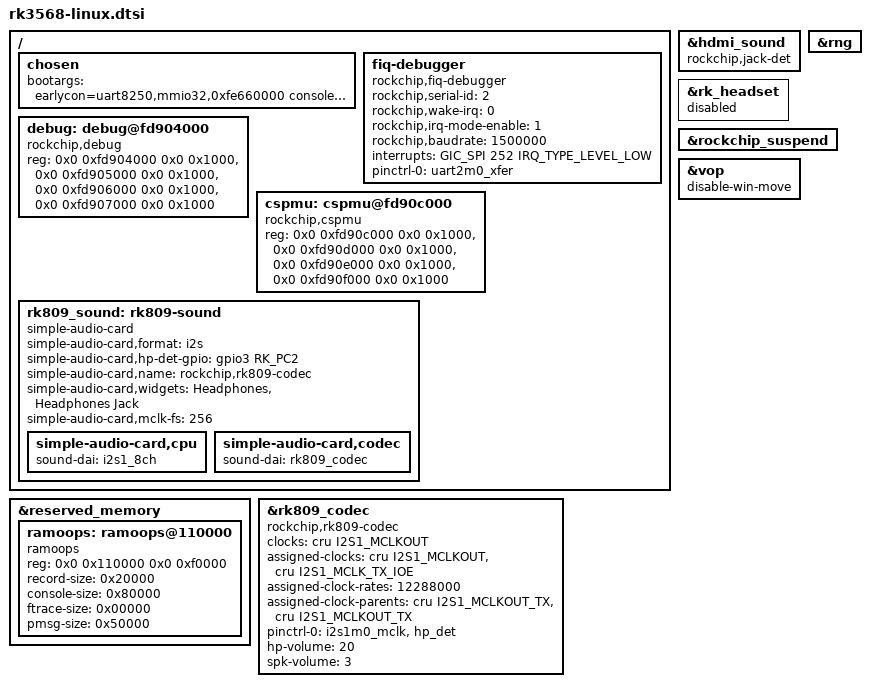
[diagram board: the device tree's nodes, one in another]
// SPDX-License-Identifier: (GPL-2.0+ OR MIT)
/*
 * Copyright (c) 2020 Rockchip Electronics Co., Ltd.
 *
 */

/ {
	chosen: chosen {
		bootargs = "earlycon=uart8250,mmio32,0xfe660000 console=ttyFIQ0 root=PARTLABEL=rootfs rootfstype=ext4 ro rootwait overlayroot=device:dev=PARTLABEL=userdata,fstype=ext4,mkfs=1 coherent_pool=1m systemd.gpt_auto=0 cgroup_enable=memory swapaccount=1";
	};

	fiq-debugger {
		compatible = "rockchip,fiq-debugger";
		rockchip,serial-id = <2>;
		rockchip,wake-irq = <0>;
		/* If enable uart uses irq instead of fiq */
		rockchip,irq-mode-enable = <1>;
		rockchip,baudrate = <1500000>;  /* Only 115200 and 1500000 */
		interrupts = <GIC_SPI 252 IRQ_TYPE_LEVEL_LOW>;
		pinctrl-names = "default";
		pinctrl-0 = <&uart2m0_xfer>;
		status = "okay";
	};

	debug: debug@fd904000 {
		compatible = "rockchip,debug";
		reg = <0x0 0xfd904000 0x0 0x1000>,
			<0x0 0xfd905000 0x0 0x1000>,
			<0x0 0xfd906000 0x0 0x1000>,
			<0x0 0xfd907000 0x0 0x1000>;
	};

	cspmu: cspmu@fd90c000 {
		compatible = "rockchip,cspmu";
		reg = <0x0 0xfd90c000 0x0 0x1000>,
			<0x0 0xfd90d000 0x0 0x1000>,
			<0x0 0xfd90e000 0x0 0x1000>,
			<0x0 0xfd90f000 0x0 0x1000>;
	};

	rk809_sound: rk809-sound {
		status = "okay";
		compatible = "simple-audio-card";
		simple-audio-card,format = "i2s";
		simple-audio-card,hp-det-gpio = <&gpio3 RK_PC2 GPIO_ACTIVE_HIGH>;
		simple-audio-card,name = "rockchip,rk809-codec";
		simple-audio-card,widgets = "Headphones", "Headphones Jack";
		simple-audio-card,mclk-fs = <256>;
		simple-audio-card,cpu {
			sound-dai = <&i2s1_8ch>;
		};
		simple-audio-card,codec {
			sound-dai = <&rk809_codec>;
		};
	};
};

&hdmi_sound {
	status = "okay";
	rockchip,jack-det;
};

&reserved_memory {
	ramoops: ramoops@110000 {
		compatible = "ramoops";
		reg = <0x0 0x110000 0x0 0xf0000>;
		record-size = <0x20000>;
		console-size = <0x80000>;
		ftrace-size = <0x00000>;
		pmsg-size = <0x50000>;
	};
};

&rk809_codec {
	#sound-dai-cells = <0>;
	compatible = "rockchip,rk809-codec", "rockchip,rk817-codec";
	clocks = <&cru I2S1_MCLKOUT>;
	clock-names = "mclk";
	assigned-clocks = <&cru I2S1_MCLKOUT>, <&cru I2S1_MCLK_TX_IOE>;
	assigned-clock-rates = <12288000>;
	assigned-clock-parents = <&cru I2S1_MCLKOUT_TX>, <&cru I2S1_MCLKOUT_TX>;
	pinctrl-names = "default";
	pinctrl-0 = <&i2s1m0_mclk &hp_det>;
	hp-volume = <20>;
	spk-volume = <3>;
	status = "okay";
};

&rk_headset {
	status = "disabled";
};

&rng {
	status = "okay";
};

&rockchip_suspend {
	status = "okay";
};

&vop {
	disable-win-move;
};
